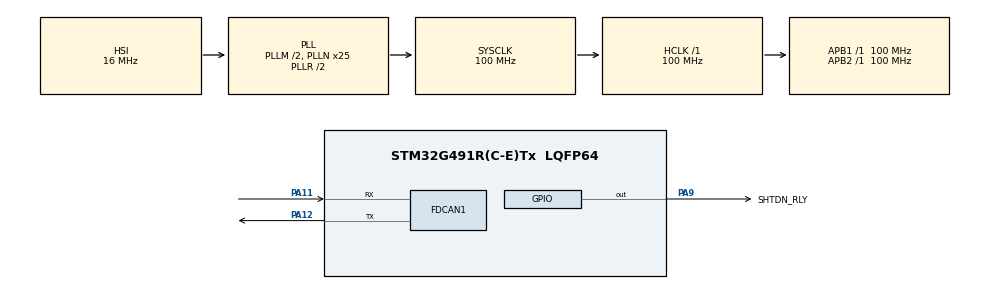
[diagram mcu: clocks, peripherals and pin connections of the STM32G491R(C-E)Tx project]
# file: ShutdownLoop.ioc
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FDCAN1.CalculateBaudRateNominal=1000000
FDCAN1.CalculateTimeBitNominal=1000
FDCAN1.CalculateTimeQuantumNominal=50.0
FDCAN1.NominalPrescaler=5
FDCAN1.NominalTimeSeg1=17
FDCAN1.StdFiltersNbr=1
Mcu.Family=STM32G4
Mcu.Name=STM32G491R(C-E)Tx
Mcu.Package=LQFP64
NVIC.PriorityGroup=NVIC_PRIORITYGROUP_4
NVIC.TIM6_DAC_IRQn=true\:0\:0\:false\:false\:true\:true\:true\:true
PA11.Mode=FDCAN_Activate
PA11.Signal=FDCAN1_RX
PA12.Mode=FDCAN_Activate
PA12.Signal=FDCAN1_TX
PA13.GPIO_Label=T_SWDIO
PA13.Mode=Serial_Wire
PA13.Signal=SYS_JTMS-SWDIO
PA14.GPIO_Label=T_SWCLK
PA14.Mode=Serial_Wire
PA14.Signal=SYS_JTCK-SWCLK
PA9.GPIO_Label=SHTDN_RLY
PA9.Signal=GPIO_Output
PF0-OSC_IN.Mode=HSE-External-Oscillator
PF0-OSC_IN.Signal=RCC_OSC_IN
PF1-OSC_OUT.Mode=HSE-External-Oscillator
PF1-OSC_OUT.Signal=RCC_OSC_OUT
ProjectManager.HeapSize=0x200
ProjectManager.StackSize=0x400
ProjectManager.TargetToolchain=STM32CubeIDE
RCC.ADC12Freq_Value=100000000
RCC.ADC345Freq_Value=100000000
RCC.AHBFreq_Value=100000000
RCC.APB1Freq_Value=100000000
RCC.APB1TimFreq_Value=100000000
RCC.APB2Freq_Value=100000000
RCC.APB2TimFreq_Value=100000000
RCC.CortexFreq_Value=100000000
RCC.EXTERNAL_CLOCK_VALUE=12288000
RCC.HCLKFreq_Value=100000000
RCC.HSE_VALUE=24000000
RCC.HSI48_VALUE=48000000
RCC.HSI_VALUE=16000000
RCC.LSE_VALUE=32768
RCC.PLLM=RCC_PLLM_DIV2
RCC.PLLN=25
RCC.RTCClockSelection=RCC_RTCCLKSOURCE_LSE
RCC.SYSCLKFreq_VALUE=100000000
RCC.SYSCLKSource=RCC_SYSCLKSOURCE_PLLCLK
RCC.USBFreq_Value=48000000
RCC.VCOOutputFreq_Value=200000000
TIM6.PeriodNoDither=1000-1
TIM6.Prescaler=500-1
VP_SYS_VS_DBSignals.Mode=DisableDeadBatterySignals
VP_TIM6_VS_ClockSourceINT.Mode=Enable_Timer
board=NUCLEO-G491RE

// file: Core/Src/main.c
/* USER CODE BEGIN Header */
/**
  ******************************************************************************
  * @file           : main.c
  * @brief          : Main program body
  ******************************************************************************
  * @attention
  *
  * Copyright (c) 2024 STMicroelectronics.
  * All rights reserved.
  *
  * This software is licensed under terms that can be found in the LICENSE file
  * in the root directory of this software component.
  * If no LICENSE file comes with this software, it is provided AS-IS.
  *
  ******************************************************************************
  */
/* USER CODE END Header */
#include "main.h"

/* USER CODE BEGIN Includes */
#include "mp7_fdcan.h"

/* USER CODE END Includes */

FDCAN_HandleTypeDef hfdcan1;

TIM_HandleTypeDef htim6;

/* USER CODE BEGIN PV */

uint8_t readyToDrive;
uint8_t throttleMessageWatchdogFlag;

#define RTD_MESSAGE_ID 0b00000100000
#define RTD_MESSAGE_DLC 0

#define THROTTLE_MESSAGE_ID 0b00001110011
#define THROTTLE_MESSAGE_DLC 4

/* USER CODE END PV */

void SystemClock_Config(void);
static void MX_GPIO_Init(void);
static void MX_FDCAN1_Init(void);
static void MX_TIM6_Init(void);

int main(void)
{

  /* MCU Configuration--------------------------------------------------------*/

  /* Reset of all peripherals, Initializes the Flash interface and the Systick. */
  HAL_Init();

  /* Configure the system clock */
  SystemClock_Config();

  /* Initialize all configured peripherals */
  MX_GPIO_Init();
  MX_FDCAN1_Init();
  MX_TIM6_Init();

  /* Infinite loop */
  /* USER CODE BEGIN WHILE */

  while (1)
  {
    // Wait for CAN messages
    /* USER CODE END WHILE */

  }
}

void SystemClock_Config(void)
{
  RCC_OscInitTypeDef RCC_OscInitStruct = {0};
  RCC_ClkInitTypeDef RCC_ClkInitStruct = {0};

  /** Configure the main internal regulator output voltage
  */
  HAL_PWREx_ControlVoltageScaling(PWR_REGULATOR_VOLTAGE_SCALE1);

  /** Initializes the RCC Oscillators according to the specified parameters
  * in the RCC_OscInitTypeDef structure.
  */
  RCC_OscInitStruct.OscillatorType = RCC_OSCILLATORTYPE_HSI;
  RCC_OscInitStruct.HSIState = RCC_HSI_ON;
  RCC_OscInitStruct.HSICalibrationValue = RCC_HSICALIBRATION_DEFAULT;
  RCC_OscInitStruct.PLL.PLLState = RCC_PLL_ON;
  RCC_OscInitStruct.PLL.PLLSource = RCC_PLLSOURCE_HSI;
  RCC_OscInitStruct.PLL.PLLM = RCC_PLLM_DIV2;
  RCC_OscInitStruct.PLL.PLLN = 25;
  RCC_OscInitStruct.PLL.PLLP = RCC_PLLP_DIV2;
  RCC_OscInitStruct.PLL.PLLQ = RCC_PLLQ_DIV2;
  RCC_OscInitStruct.PLL.PLLR = RCC_PLLR_DIV2;
  if (HAL_RCC_OscConfig(&RCC_OscInitStruct) != HAL_OK)
  {
    Error_Handler();
  }

  /** Initializes the CPU, AHB and APB buses clocks
  */
  RCC_ClkInitStruct.ClockType = RCC_CLOCKTYPE_HCLK|RCC_CLOCKTYPE_SYSCLK
                              |RCC_CLOCKTYPE_PCLK1|RCC_CLOCKTYPE_PCLK2;
  RCC_ClkInitStruct.SYSCLKSource = RCC_SYSCLKSOURCE_PLLCLK;
  RCC_ClkInitStruct.AHBCLKDivider = RCC_SYSCLK_DIV1;
  RCC_ClkInitStruct.APB1CLKDivider = RCC_HCLK_DIV1;
  RCC_ClkInitStruct.APB2CLKDivider = RCC_HCLK_DIV1;

  if (HAL_RCC_ClockConfig(&RCC_ClkInitStruct, FLASH_LATENCY_3) != HAL_OK)
  {
    Error_Handler();
  }
}

static void MX_FDCAN1_Init(void)
{

  hfdcan1.Instance = FDCAN1;
  hfdcan1.Init.ClockDivider = FDCAN_CLOCK_DIV1;
  hfdcan1.Init.FrameFormat = FDCAN_FRAME_CLASSIC;
  hfdcan1.Init.Mode = FDCAN_MODE_NORMAL;
  hfdcan1.Init.AutoRetransmission = DISABLE;
  hfdcan1.Init.TransmitPause = DISABLE;
  hfdcan1.Init.ProtocolException = DISABLE;
  hfdcan1.Init.NominalPrescaler = 5;
  hfdcan1.Init.NominalSyncJumpWidth = 1;
  hfdcan1.Init.NominalTimeSeg1 = 17;
  hfdcan1.Init.NominalTimeSeg2 = 2;
  hfdcan1.Init.DataPrescaler = 1;
  hfdcan1.Init.DataSyncJumpWidth = 1;
  hfdcan1.Init.DataTimeSeg1 = 1;
  hfdcan1.Init.DataTimeSeg2 = 1;
  hfdcan1.Init.StdFiltersNbr = 1;
  hfdcan1.Init.ExtFiltersNbr = 0;
  hfdcan1.Init.TxFifoQueueMode = FDCAN_TX_FIFO_OPERATION;
  if (HAL_FDCAN_Init(&hfdcan1) != HAL_OK)
  {
    Error_Handler();
  }
  /* USER CODE BEGIN FDCAN1_Init 2 */

  if (MP7_FDCAN_ConfigureGlobalFilter(&hfdcan1) != HAL_OK) {
    Error_Handler();
  }

  if (MP7_FDCAN_ConfigureFilter(&hfdcan1, MP7_HIGH_PRIORITY_MIN_ID, MP7_LOW_PRIORITY_MAX_ID, 0, FDCAN_FILTER_TO_RXFIFO0) != HAL_OK) {
    Error_Handler();
  }

  if (HAL_FDCAN_Start(&hfdcan1) != HAL_OK) {
    Error_Handler();
  }

  if (HAL_FDCAN_ActivateNotification(&hfdcan1, FDCAN_IT_RX_FIFO0_NEW_MESSAGE, 0) != HAL_OK) {
    Error_Handler();
  }

  /* USER CODE END FDCAN1_Init 2 */

}

static void MX_TIM6_Init(void)
{

  TIM_MasterConfigTypeDef sMasterConfig = {0};

  htim6.Instance = TIM6;
  htim6.Init.Prescaler = 500-1;
  htim6.Init.CounterMode = TIM_COUNTERMODE_UP;
  htim6.Init.Period = 999;
  htim6.Init.AutoReloadPreload = TIM_AUTORELOAD_PRELOAD_DISABLE;
  if (HAL_TIM_Base_Init(&htim6) != HAL_OK)
  {
    Error_Handler();
  }
  sMasterConfig.MasterOutputTrigger = TIM_TRGO_RESET;
  sMasterConfig.MasterSlaveMode = TIM_MASTERSLAVEMODE_DISABLE;
  if (HAL_TIMEx_MasterConfigSynchronization(&htim6, &sMasterConfig) != HAL_OK)
  {
    Error_Handler();
  }

}

static void MX_GPIO_Init(void)
{
  GPIO_InitTypeDef GPIO_InitStruct = {0};

  /* GPIO Ports Clock Enable */
  __HAL_RCC_GPIOF_CLK_ENABLE();
  __HAL_RCC_GPIOA_CLK_ENABLE();

  /*Configure GPIO pin Output Level */
  HAL_GPIO_WritePin(SHTDN_RLY_GPIO_Port, SHTDN_RLY_Pin, GPIO_PIN_RESET);

  /*Configure GPIO pin : SHTDN_RLY_Pin */
  GPIO_InitStruct.Pin = SHTDN_RLY_Pin;
  GPIO_InitStruct.Mode = GPIO_MODE_OUTPUT_PP;
  GPIO_InitStruct.Pull = GPIO_NOPULL;
  GPIO_InitStruct.Speed = GPIO_SPEED_FREQ_LOW;
  HAL_GPIO_Init(SHTDN_RLY_GPIO_Port, &GPIO_InitStruct);

}

/* USER CODE BEGIN 4 */

void HAL_FDCAN_RxFifo0Callback(FDCAN_HandleTypeDef *hfdcan, uint32_t RxFifo0ITs) {
  FDCAN_RxHeaderTypeDef rxHeader;
  uint8_t rxData[8];
  if((RxFifo0ITs & FDCAN_IT_RX_FIFO0_NEW_MESSAGE) != 0) {
    if(HAL_FDCAN_GetRxMessage(&hfdcan1, FDCAN_RX_FIFO0, &rxHeader, rxData) != HAL_OK) {
      Error_Handler();
    }

    if (readyToDrive == 0) {
      if (rxHeader.Identifier == RTD_MESSAGE_ID && rxHeader.DataLength == RTD_MESSAGE_DLC) {
        readyToDrive = 1;
        if (HAL_TIM_Base_Start_IT(&htim6) != HAL_OK) { // Start throttle watchdog
          Error_Handler();
        }

        // Turn on safety circuit relay
        HAL_GPIO_WritePin(SHTDN_RLY_GPIO_Port, SHTDN_RLY_Pin, 1);
      }
    } else {
      if (rxHeader.Identifier == THROTTLE_MESSAGE_ID && rxHeader.DataLength == THROTTLE_MESSAGE_DLC) {
        throttleMessageWatchdogFlag = 1;
      }
    }

  }
}

void HAL_TIM_PeriodElapsedCallback(TIM_HandleTypeDef *htim) {
  // Timer expired
  if (throttleMessageWatchdogFlag == 0) {
    // Throttle message not received
    Error_Handler();
  } else {
    throttleMessageWatchdogFlag = 0;
  }
}

/* USER CODE END 4 */

void Error_Handler(void)
{
  /* USER CODE BEGIN Error_Handler_Debug */
  /* User can add his own implementation to report the HAL error return state */
  __disable_irq();

  // Turn off the safety circuit relay to shut down the car
  HAL_GPIO_WritePin(SHTDN_RLY_GPIO_Port, SHTDN_RLY_Pin, 0);

  while (1)
  {
  }
  /* USER CODE END Error_Handler_Debug */
}
